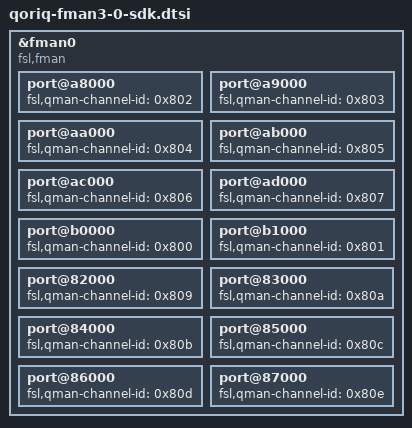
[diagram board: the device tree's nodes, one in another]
&fman0 {
	compatible = "fsl,fman", "simple-bus";

	/* tx - 10g - 2 */
	port@a8000 {
		fsl,qman-channel-id = <0x802>;
	};
	/* tx - 10g - 3 */
	port@a9000 {
		fsl,qman-channel-id = <0x803>;
	};
	/* tx - 1g - 2 */
	port@aa000 {
		fsl,qman-channel-id = <0x804>;
	};
	/* tx - 1g - 3 */
	port@ab000 {
		fsl,qman-channel-id = <0x805>;
	};
	/* tx - 1g - 4 */
	port@ac000 {
		fsl,qman-channel-id = <0x806>;
	};
	/* tx - 1g - 5 */
	port@ad000 {
		fsl,qman-channel-id = <0x807>;
	};
	/* tx - 10g - 0 */
	port@b0000 {
		fsl,qman-channel-id = <0x800>;
	};
	/* tx - 10g - 1 */
	port@b1000 {
		fsl,qman-channel-id = <0x801>;
	};
	/* offline - 1 */
	port@82000 {
		fsl,qman-channel-id = <0x809>;
	};
	/* offline - 2 */
	port@83000 {
		fsl,qman-channel-id = <0x80a>;
	};
	/* offline - 3 */
	port@84000 {
		fsl,qman-channel-id = <0x80b>;
	};
	/* offline - 4 */
	port@85000 {
		fsl,qman-channel-id = <0x80c>;
	};
	/* offline - 5 */
	port@86000 {
		fsl,qman-channel-id = <0x80d>;
	};
	/* offline - 6 */
	port@87000 {
		fsl,qman-channel-id = <0x80e>;
	};
};
